# RL7005_IP_SVD register map
Vendor: Realtek
IP svd file
Registers are 32-bit, read-write, reset 0x0 unless marked. A register's access mark holds for its fields unless they carry their own. Offsets are from the block's base; lines under a group give offsets from that group; [hi:lo] are bit positions; {n}, {i} and the like mark numbered series; 'fields as' and 'values as' point back to an identical list; <NAME> marks a mode.

## Memory map
0x40000000 PAGE0 size 0x100
0x40000000 PAGE1 size 0x1200
0x40000000 PAGE2 size 0x300
0x40000000 PAGE3 size 0x1310
0x40000000 PAGE4 size 0x14A4
0x40000000 PAGE5 size 0x15C4
0x40000000 PAGE6 size 0x1700
0x40000000 PAGE7 size 0x800
0x40000000 PAGE17 size 0x1800
0x40000000 PAGE26 size 0x2620
0x40000000 TXPWR_CTRL size 0xDB04
0x40000000 MAC_SRAM size 0x54004
0x400B1000 UVC_REG size 0x180
0x400C0000 PKE_REG size 0x3C
0x40100000 LCDC_REG size 0x100
0x40111000 SDIO_WIFI_REG size 0xE4
0x40112000 SDIO_BT_REG size 0xDC
0x40114000 SDIO size 0xB88
0x40118000 SPORT0_REG size 0x984
0x4011A000 RMII_REG size 0x1440
0x4011D000 SPI_FLASH_CTRL size 0x400
0x4011E000 PSRAM_REG size 0x400
0x4011F000 PSRAM_PHY_REG size 0xFC
0x40120000 GDMA0_REG size 0x400
0x40121000 SPI0_REG size 0xB0C
0x40122000 SPI1_REG size 0xB0C
0x40123000 AES_REG size 0x1000
0x40124000 SHA_REG size 0x1000
0x40125000 AES_SHA_DMA_REG size 0x400
0x40126000 PPE_REG size 0x1D0
0x40800000 OTPC_REG size 0x744
0x40808000 AES_KEY_REG size 0x90
0x4080A000 LP_AON size 0x100
0x4080A100 LDO_REG size 0x80
0x4080A180 SWR_REG size 0x80
0x4080A200 LP_SYS size 0x100
0x4080A300 PMC size 0x94
0x4080A400 XTAL_REG size 0x50
0x4080A480 WLAFE_REG size 0x40
0x4080A500 PLL_REG size 0x68
0x4080A600 SYSTEM_MEM_CTRL size 0x200
0x4080A800 PINMUX_REG size 0x200
0x4080AA00 RTC_REG size 0x2C
0x4080AA80 RTC_MISC size 0xC
0x4080AC00 IWDG_REG size 0x14
0x4080AD00 WDG0_REG size 0x14
0x4080AD80 WDG2_REG size 0x14
0x4080B000 SDM_REG size 0x24
0x4080B200 LEDC_REG size 0x84
0x4080C000 UART0_REG size 0x68
0x4080D000 UART1_REG size 0x68
0x4080E000 UART2_REG size 0x68
0x4080F000 UART3_REG size 0x68
0x40810000 UARTLOG_REG size 0xF4
0x40811000 GPIO_REG size 0x100
0x40812000 ADC_REG size 0x104
0x40813000 CTC_REG size 0x228
0x40814000 SHA_KEY_REG size 0x50
0x40815000 IPC0_REG size 0x3C
0x40815080 IPC1_REG size 0x3C
0x40816000 THERMAL_REG size 0x34
0x40817000 DEBUGTIMER_REG size 0x1C
0x40818000 PMC_TIMER_REG size 0x34
0x40819000 TIMER0_REG size 0x58
0x40819200 TIMER1_REG size 0x58
0x40819400 TIMER2_REG size 0x58
0x40819600 TIMER3_REG size 0x58
0x41000000 TIMER4_REG size 0x58
0x41000200 TIMER5_REG size 0x58
0x41000400 TIMER6_REG size 0x58
0x41000600 TIMER7_REG size 0x58
0x41000800 TIMER8_REG size 0x58
0x41000A00 UPS_REG size 0x58
0x41001000 TRNG_REG size 0x21C
0x41002000 RXI300_REG size 0xE040
0x41004000 RSIP_REG size 0x300
0x41005000 CAN0_REG size 0x400
0x41006000 CAN1_REG size 0x400
0x41007000 IR_REG size 0x34
0x41008000 I2C0_REG size 0x104
0x41009000 I2C1_REG size 0x104
0x4100A000 AUDIO_REG size 0x82C
0x5080AD40 WDG1_REG_S size 0x14
0x5080B400 CPU_MMU_S size 0x70
0x51002200 MPC1_S size 0xE040
0x51002300 MPC2_S size 0xE040
0x51002400 MPC3_S size 0xE040
0x51002500 PPC_S size 0xE040

## CPU_MMU_S
Base 0x5080B400
{0x0+0xC*i} REG_REMAP{i}BAR_CPU0 (i=0..3)
  [31:10] remap_bar{i}_cpu0 — cpu0 mmu base addr for entry{i} Note:[31:20] not used for mmu only for sram and rom
{0x4+0xC*i} REG_REMAP{i}EAR_CPU0 (i=0..3)
  [31:10] remap_ear{i}_cpu0 — cpu0 mmu end addr for entry{i} Note:[31:20] not used for mmu only for sram and rom
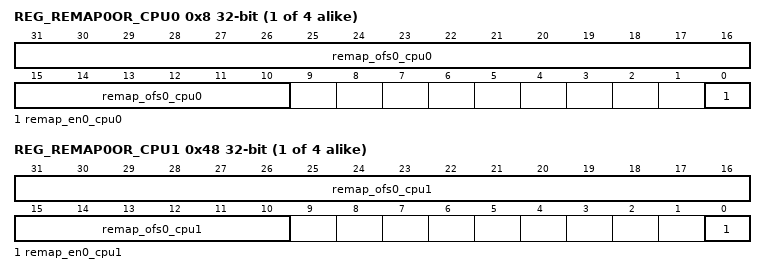
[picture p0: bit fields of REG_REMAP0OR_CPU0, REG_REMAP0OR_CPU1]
{0x8+0xC*i} REG_REMAP{i}OR_CPU0 (i=0..3)
  [31:10] remap_ofs{i}_cpu0 — cpu0 mmu offset addr when hit entry{i}. MMU unit in 1KB, so [9:0] is no used. HW always add this value to acture addr when hit , if need to sub, set this value to 2-comp minus value. Note:[31:20] not used for mmu only for sram and rom
  [0] remap_en{i}_cpu0 — cpu0 mmu enable for entry{i}
{0x40+0xC*i} REG_REMAP{i}BAR_CPU1 (i=0..3)
  [31:10] remap_bar{i}_cpu1 — cpu1 mmu base addr for entry{i} Note:[31:20] not used for mmu only for sram and rom
{0x44+0xC*i} REG_REMAP{i}EAR_CPU1 (i=0..3)
  [31:10] remap_ear{i}_cpu1 — cpu1 mmu end addr for entry{i} Note:[31:20] not used for mmu only for sram and rom
{0x48+0xC*i} REG_REMAP{i}OR_CPU1 (i=0..3)
  [31:10] remap_ofs{i}_cpu1 — cpu1 mmu offset addr when hit entry{i}. MMU unit in 1KB, so [9:0] is no used. HW always add this value to acture addr when hit , if need to sub, set this value to 2-comp minus value. Note:[31:20] not used for mmu only for sram and rom
  [0] remap_en{i}_cpu1 — cpu1 mmu enable for entry{i}

## Notices in the file
Copyright (C) 2012-2025 Realsil Limited. All rights reserved.
